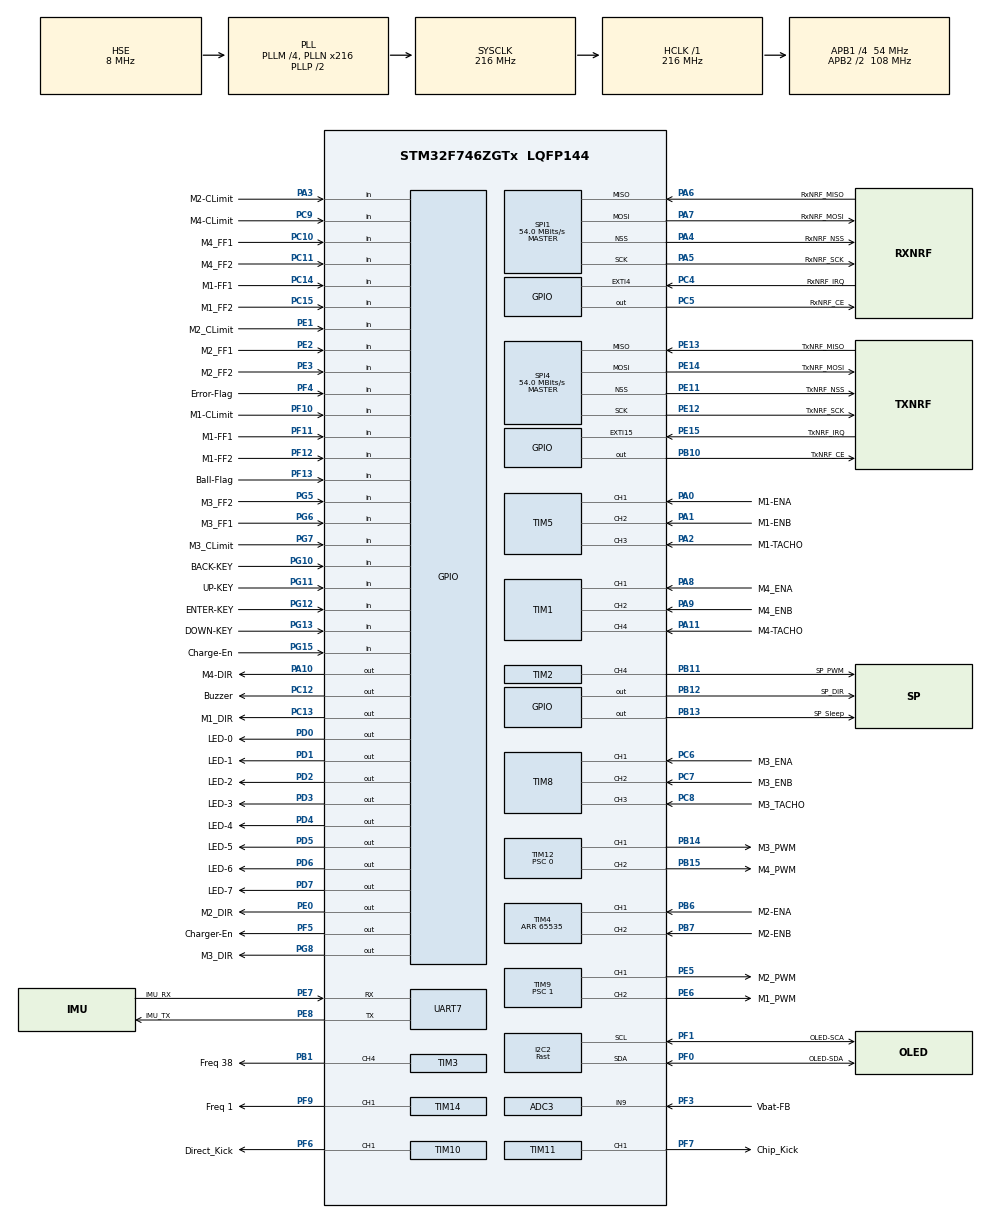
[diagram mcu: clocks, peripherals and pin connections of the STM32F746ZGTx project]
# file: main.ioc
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ADC3.Channel-9\#ChannelRegularConversion=ADC_CHANNEL_9
ADC3.ClockPrescaler=ADC_CLOCK_SYNC_PCLK_DIV4
ADC3.ContinuousConvMode=ENABLE
ADC3.DMAContinuousRequests=DISABLE
ADC3.DataAlign=ADC_DATAALIGN_RIGHT
ADC3.DiscontinuousConvMode=DISABLE
ADC3.EOCSelection=ADC_EOC_SINGLE_CONV
ADC3.EnableAnalogWatchDog=false
ADC3.ExternalTrigConv=ADC_SOFTWARE_START
ADC3.ExternalTrigConvEdge=ADC_EXTERNALTRIGCONVEDGE_NONE
ADC3.InjNumberOfConversion=0
ADC3.NbrOfConversion=1
ADC3.NbrOfConversionFlag=1
ADC3.Rank-9\#ChannelRegularConversion=1
ADC3.Resolution=ADC_RESOLUTION_10B
ADC3.SamplingTime-9\#ChannelRegularConversion=ADC_SAMPLETIME_480CYCLES
ADC3.ScanConvMode=DISABLE
I2C2.I2C_Speed_Mode=I2C_Fast
I2C2.Timing=0x6000030D
Mcu.Family=STM32F7
Mcu.Name=STM32F746ZGTx
Mcu.Package=LQFP144
NVIC.ADC_IRQn=true\:0\:0\:false\:false\:true\:true
NVIC.PriorityGroup=NVIC_PRIORITYGROUP_4
NVIC.TIM6_DAC_IRQn=true\:0\:0\:false\:false\:true\:true
NVIC.TIM7_IRQn=true\:0\:0\:false\:false\:true\:true
NVIC.TIM8_UP_TIM13_IRQn=true\:0\:0\:false\:false\:true\:true
NVIC.UART7_IRQn=true\:0\:0\:false\:false\:true\:true
PA0/WKUP.GPIO_Label=M1-ENA
PA0/WKUP.Signal=S_TIM5_CH1
PA1.GPIO_Label=M1-ENB
PA1.Signal=S_TIM5_CH2
PA10.GPIO_Label=M4-DIR
PA10.Signal=GPIO_Output
PA11.GPIO_Label=M4-TACHO
PA11.Signal=S_TIM1_CH4
PA13.Mode=Serial_Wire
PA13.Signal=SYS_JTMS-SWDIO
PA14.Mode=Serial_Wire
PA14.Signal=SYS_JTCK-SWCLK
PA2.GPIO_Label=M1-TACHO
PA2.Signal=S_TIM5_CH3
PA3.GPIO_Label=M2-CLimit
PA3.Signal=GPIO_Input
PA4.GPIO_Label=RxNRF_NSS
PA4.Mode=NSS_Signal_Hard_Output
PA4.Signal=SPI1_NSS
PA5.GPIO_Label=RxNRF_SCK
PA5.Mode=Full_Duplex_Master
PA5.Signal=SPI1_SCK
PA6.GPIO_Label=RxNRF_MISO
PA6.Mode=Full_Duplex_Master
PA6.Signal=SPI1_MISO
PA7.GPIO_Label=RxNRF_MOSI
PA7.Mode=Full_Duplex_Master
PA7.Signal=SPI1_MOSI
PA8.GPIO_Label=M4_ENA
PA8.Signal=S_TIM1_CH1
PA9.GPIO_Label=M4_ENB
PA9.Signal=S_TIM1_CH2
PB1.GPIO_Label=Freq 38
PB1.GPIO_Speed=GPIO_SPEED_FREQ_VERY_HIGH
PB1.Signal=S_TIM3_CH4
PB10.GPIO_Label=TxNRF_CE
PB10.Signal=GPIO_Output
PB11.GPIO_Label=SP_PWM
PB11.Signal=S_TIM2_CH4
PB12.GPIO_Label=SP_DIR
PB12.Signal=GPIO_Output
PB13.GPIO_Label=SP_Sleep
PB13.Signal=GPIO_Output
PB14.GPIO_Label=M3_PWM
PB14.GPIO_Speed=GPIO_SPEED_FREQ_HIGH
PB14.Signal=S_TIM12_CH1
PB15.GPIO_Label=M4_PWM
PB15.GPIO_Speed=GPIO_SPEED_FREQ_HIGH
PB15.Signal=S_TIM12_CH2
PB6.GPIO_Label=M2-ENA
PB6.Signal=S_TIM4_CH1
PB7.GPIO_Label=M2-ENB
PB7.Signal=S_TIM4_CH2
PB9.GPIO_Label=M2_TACHO
PB9.Signal=S_TIM4_CH4
PC10.GPIO_Label=M4_FF1
PC10.Signal=GPIO_Input
PC11.GPIO_Label=M4_FF2
PC11.Signal=GPIO_Input
PC12.GPIO_Label=Buzzer
PC12.Signal=GPIO_Output
PC13.GPIO_Label=M1_DIR
PC13.Signal=GPIO_Output
PC14/OSC32_IN.GPIO_Label=M1-FF1
PC14/OSC32_IN.Signal=GPIO_Input
PC15/OSC32_OUT.GPIO_Label=M1_FF2
PC15/OSC32_OUT.Signal=GPIO_Input
PC4.GPIO_Label=RxNRF_IRQ
PC4.Signal=GPXTI4
PC5.GPIO_Label=RxNRF_CE
PC5.Signal=GPIO_Output
PC6.GPIO_Label=M3_ENA
PC6.Signal=S_TIM8_CH1
PC7.GPIO_Label=M3_ENB
PC7.Signal=S_TIM8_CH2
PC8.GPIO_Label=M3_TACHO
PC8.Signal=S_TIM8_CH3
PC9.GPIO_Label=M4-CLimit
PC9.Signal=GPIO_Input
PD0.GPIO_Label=LED-0
PD0.Signal=GPIO_Output
PD1.GPIO_Label=LED-1
PD1.Signal=GPIO_Output
PD2.GPIO_Label=LED-2
PD2.Signal=GPIO_Output
PD3.GPIO_Label=LED-3
PD3.Signal=GPIO_Output
PD4.GPIO_Label=LED-4
PD4.Signal=GPIO_Output
PD5.GPIO_Label=LED-5
PD5.Signal=GPIO_Output
PD6.GPIO_Label=LED-6
PD6.Signal=GPIO_Output
PD7.GPIO_Label=LED-7
PD7.Signal=GPIO_Output
PE0.GPIO_Label=M2_DIR
PE0.Signal=GPIO_Output
PE1.GPIO_Label=M2_CLimit
PE1.Signal=GPIO_Input
PE11.GPIO_Label=TxNRF_NSS
PE11.Mode=NSS_Signal_Hard_Output
PE11.Signal=SPI4_NSS
PE12.GPIO_Label=TxNRF_SCK
PE12.Mode=Full_Duplex_Master
PE12.Signal=SPI4_SCK
PE13.GPIO_Label=TxNRF_MISO
PE13.Mode=Full_Duplex_Master
PE13.Signal=SPI4_MISO
PE14.GPIO_Label=TxNRF_MOSI
PE14.Mode=Full_Duplex_Master
PE14.Signal=SPI4_MOSI
PE15.GPIO_Label=TxNRF_IRQ
PE15.Signal=GPXTI15
PE2.GPIO_Label=M2_FF1
PE2.Signal=GPIO_Input
PE3.GPIO_Label=M2_FF2
PE3.Signal=GPIO_Input
PE5.GPIO_Label=M2_PWM
PE5.GPIO_Speed=GPIO_SPEED_FREQ_HIGH
PE5.Signal=S_TIM9_CH1
PE6.GPIO_Label=M1_PWM
PE6.GPIO_Speed=GPIO_SPEED_FREQ_HIGH
PE6.Signal=S_TIM9_CH2
PE7.GPIO_Label=IMU_RX
PE7.Mode=Asynchronous
PE7.Signal=UART7_RX
PE8.GPIO_Label=IMU_TX
PE8.Mode=Asynchronous
PE8.Signal=UART7_TX
PF0.GPIO_Label=OLED-SDA
PF0.Mode=I2C
PF0.Signal=I2C2_SDA
PF1.GPIO_Label=OLED-SCA
PF1.Mode=I2C
PF1.Signal=I2C2_SCL
PF10.GPIO_Label=M1-CLimit
PF10.Signal=GPIO_Input
PF11.GPIO_Label=M1-FF1
PF11.Signal=GPIO_Input
PF12.GPIO_Label=M1-FF2
PF12.Signal=GPIO_Input
PF13.GPIO_Label=Ball-Flag
PF13.Signal=GPIO_Input
PF3.GPIO_Label=Vbat-FB
PF3.Mode=IN9
PF3.Signal=ADC3_IN9
PF4.GPIO_Label=Error-Flag
PF4.Signal=GPIO_Input
PF5.GPIO_Label=Charger-En
PF5.Signal=GPIO_Output
PF6.GPIO_Label=Direct_Kick
PF6.GPIO_ModeDefaultPP=GPIO_MODE_AF_PP
PF6.GPIO_PuPd=GPIO_NOPULL
PF6.GPIO_Speed=GPIO_SPEED_FREQ_VERY_HIGH
PF6.Signal=S_TIM10_CH1
PF7.GPIO_Label=Chip_Kick
PF7.GPIO_Speed=GPIO_SPEED_FREQ_VERY_HIGH
PF7.Signal=S_TIM11_CH1
PF9.GPIO_Label=Freq 1 
PF9.GPIO_Speed=GPIO_SPEED_FREQ_VERY_HIGH
PF9.Signal=S_TIM14_CH1
PG10.GPIO_Label=BACK-KEY
PG10.Signal=GPIO_Input
PG11.GPIO_Label=UP-KEY
PG11.Signal=GPIO_Input
PG12.GPIO_Label=ENTER-KEY
PG12.Signal=GPIO_Input
PG13.GPIO_Label=DOWN-KEY
PG13.Signal=GPIO_Input
PG15.GPIO_Label=Charge-En
PG15.Signal=GPIO_Input
PG5.GPIO_Label=M3_FF2
PG5.Signal=GPIO_Input
PG6.GPIO_Label=M3_FF1
PG6.Signal=GPIO_Input
PG7.GPIO_Label=M3_CLimit
PG7.Signal=GPIO_Input
PG8.GPIO_Label=M3_DIR
PG8.Signal=GPIO_Output
PH0/OSC_IN.Mode=HSE-External-Oscillator
PH0/OSC_IN.Signal=RCC_OSC_IN
PH1/OSC_OUT.Mode=HSE-External-Oscillator
PH1/OSC_OUT.Signal=RCC_OSC_OUT
ProjectManager.HeapSize=0x200
ProjectManager.StackSize=0x400
ProjectManager.TargetToolchain=MDK-ARM V5
RCC.AHBFreq_Value=216000000
RCC.APB1CLKDivider=RCC_HCLK_DIV4
RCC.APB1Freq_Value=54000000
RCC.APB1TimFreq_Value=108000000
RCC.APB2CLKDivider=RCC_HCLK_DIV2
RCC.APB2Freq_Value=108000000
RCC.APB2TimFreq_Value=216000000
RCC.CortexFreq_Value=216000000
RCC.HCLKFreq_Value=216000000
RCC.HSE_VALUE=8000000
RCC.HSI_VALUE=16000000
RCC.LSE_VALUE=32768
RCC.PLLM=4
RCC.PLLN=216
RCC.PLLSourceVirtual=RCC_PLLSOURCE_HSE
RCC.SYSCLKFreq_VALUE=216000000
RCC.SYSCLKSource=RCC_SYSCLKSOURCE_PLLCLK
RCC.USBFreq_Value=216000000
RCC.VCOOutputFreq_Value=432000000
SH.S_TIM10_CH1.0=TIM10_CH1,PWM Generation1 CH1
SH.S_TIM11_CH1.0=TIM11_CH1,PWM Generation1 CH1
SH.S_TIM12_CH1.0=TIM12_CH1,PWM Generation1 CH1
SH.S_TIM12_CH2.0=TIM12_CH2,PWM Generation2 CH2
SH.S_TIM14_CH1.0=TIM14_CH1,PWM Generation1 CH1
SH.S_TIM1_CH1.0=TIM1_CH1,Encoder_Interface
SH.S_TIM1_CH2.0=TIM1_CH2,Encoder_Interface
SH.S_TIM1_CH4.0=TIM1_CH4,Input_Capture4_from_TI4
SH.S_TIM2_CH4.0=TIM2_CH4,PWM Generation4 CH4
SH.S_TIM3_CH4.0=TIM3_CH4,PWM Generation4 CH4
SH.S_TIM4_CH1.0=TIM4_CH1,Encoder_Interface
SH.S_TIM4_CH2.0=TIM4_CH2,Encoder_Interface
SH.S_TIM4_CH4.0=TIM4_CH4
SH.S_TIM5_CH1.0=TIM5_CH1,Encoder_Interface
SH.S_TIM5_CH2.0=TIM5_CH2,Encoder_Interface
SH.S_TIM5_CH3.0=TIM5_CH3,Input_Capture3_from_TI3
SH.S_TIM8_CH1.0=TIM8_CH1,Encoder_Interface
SH.S_TIM8_CH2.0=TIM8_CH2,Encoder_Interface
SH.S_TIM8_CH3.0=TIM8_CH3,Input_Capture3_from_TI3
SH.S_TIM9_CH1.0=TIM9_CH1,PWM Generation1 CH1
SH.S_TIM9_CH2.0=TIM9_CH2,PWM Generation2 CH2
SPI1.BaudRatePrescaler=SPI_BAUDRATEPRESCALER_2
SPI1.CalculateBaudRate=54.0 MBits/s
SPI1.Direction=SPI_DIRECTION_2LINES
SPI1.Mode=SPI_MODE_MASTER
SPI1.VirtualNSS=VM_NSSHARD
SPI1.VirtualType=VM_MASTER
SPI4.BaudRatePrescaler=SPI_BAUDRATEPRESCALER_2
SPI4.CalculateBaudRate=54.0 MBits/s
SPI4.Direction=SPI_DIRECTION_2LINES
SPI4.Mode=SPI_MODE_MASTER
SPI4.VirtualNSS=VM_NSSHARD
SPI4.VirtualType=VM_MASTER
TIM1.Channel-Input_Capture4_from_TI4=TIM_CHANNEL_4
TIM10.Channel=TIM_CHANNEL_1
TIM10.OCFastMode_PWM=TIM_OCFAST_ENABLE
TIM10.OCMode_PWM=TIM_OCMODE_PWM2
TIM10.Period=65535
TIM10.Prescaler=11
TIM11.Channel=TIM_CHANNEL_1
TIM11.Period=65535
TIM11.Prescaler=11
TIM12.Channel-PWM\ Generation1\ CH1=TIM_CHANNEL_1
TIM12.Channel-PWM\ Generation2\ CH2=TIM_CHANNEL_2
TIM12.Period=4999
TIM12.Prescaler=0
TIM13.Period=9999
TIM13.Prescaler=1079
TIM14.Channel=TIM_CHANNEL_1
TIM14.OCMode_PWM=TIM_OCMODE_PWM1
TIM14.OCPolarity_1=TIM_OCPOLARITY_HIGH
TIM14.Period=53999
TIM14.Prescaler=1
TIM14.Pulse=27000
TIM2.Channel-PWM\ Generation4\ CH4=TIM_CHANNEL_4
TIM2.Period=4999
TIM3.Channel-PWM\ Generation4\ CH4=TIM_CHANNEL_4
TIM3.OCPolarity_4=TIM_OCPOLARITY_HIGH
TIM3.Period=2841
TIM3.Pulse-PWM\ Generation4\ CH4=1421
TIM4.EncoderMode=TIM_ENCODERMODE_TI12
TIM4.IC1Filter=15
TIM4.IC2Filter=15
TIM4.Period=65535
TIM5.Channel-Input_Capture3_from_TI3=TIM_CHANNEL_3
TIM6.Period=9999
TIM6.Prescaler=107
TIM7.Period=9999
TIM7.Prescaler=107
TIM8.Channel-Input_Capture3_from_TI3=TIM_CHANNEL_3
TIM9.Channel-PWM\ Generation1\ CH1=TIM_CHANNEL_1
TIM9.Channel-PWM\ Generation2\ CH2=TIM_CHANNEL_2
TIM9.OCFastMode_PWM-PWM\ Generation2\ CH2=TIM_OCFAST_ENABLE
TIM9.OCMode_PWM-PWM\ Generation2\ CH2=TIM_OCMODE_PWM1
TIM9.OCPolarity_2=TIM_OCPOLARITY_HIGH
TIM9.Period=4999
TIM9.Prescaler=1
VP_TIM10_VS_ClockSourceINT.Mode=Enable_Timer
VP_TIM10_VS_OPM.Mode=OPM_bit
VP_TIM11_VS_ClockSourceINT.Mode=Enable_Timer
VP_TIM11_VS_OPM.Mode=OPM_bit
VP_TIM12_VS_ClockSourceINT.Mode=Internal
VP_TIM13_VS_ClockSourceINT.Mode=Enable_Timer
VP_TIM14_VS_ClockSourceINT.Mode=Enable_Timer
VP_TIM6_VS_ClockSourceINT.Mode=Enable_Timer
VP_TIM7_VS_ClockSourceINT.Mode=Enable_Timer
VP_TIM9_VS_ClockSourceINT.Mode=Internal
board=main

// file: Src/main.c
/**
  ******************************************************************************
  * @file           : main.c
  * @brief          : Main program body
  ******************************************************************************
  ** This notice applies to any and all portions of this file
  * that are not between comment pairs USER CODE BEGIN and
  * USER CODE END. Other portions of this file, whether
  * inserted by the user or by software development tools
  * are owned by their respective copyright owners.
  *
  * COPYRIGHT(c) 2018 STMicroelectronics
  *
  * Redistribution and use in source and binary forms, with or without modification,
  * are permitted provided that the following conditions are met:
  *   1. Redistributions of source code must retain the above copyright notice,
  *      this list of conditions and the following disclaimer.
  *   2. Redistributions in binary form must reproduce the above copyright notice,
  *      this list of conditions and the following disclaimer in the documentation
  *      and/or other materials provided with the distribution.
  *   3. Neither the name of STMicroelectronics nor the names of its contributors
  *      may be used to endorse or promote products derived from this software
  *      without specific prior written permission.
  *
  * THIS SOFTWARE IS PROVIDED BY THE COPYRIGHT HOLDERS AND CONTRIBUTORS "AS IS"
  * AND ANY EXPRESS OR IMPLIED WARRANTIES, INCLUDING, BUT NOT LIMITED TO, THE
  * IMPLIED WARRANTIES OF MERCHANTABILITY AND FITNESS FOR A PARTICULAR PURPOSE ARE
  * DISCLAIMED. IN NO EVENT SHALL THE COPYRIGHT HOLDER OR CONTRIBUTORS BE LIABLE
  * FOR ANY DIRECT, INDIRECT, INCIDENTAL, SPECIAL, EXEMPLARY, OR CONSEQUENTIAL
  * DAMAGES (INCLUDING, BUT NOT LIMITED TO, PROCUREMENT OF SUBSTITUTE GOODS OR
  * SERVICES; LOSS OF USE, DATA, OR PROFITS; OR BUSINESS INTERRUPTION) HOWEVER
  * CAUSED AND ON ANY THEORY OF LIABILITY, WHETHER IN CONTRACT, STRICT LIABILITY,
  * OR TORT (INCLUDING NEGLIGENCE OR OTHERWISE) ARISING IN ANY WAY OUT OF THE USE
  * OF THIS SOFTWARE, EVEN IF ADVISED OF THE POSSIBILITY OF SUCH DAMAGE.
  *
  ******************************************************************************
  */
#include "main.h"
#include "stm32f7xx_hal.h"

/* USER CODE BEGIN Includes */

#include "stdbool.h"
#include "ssd1306.h"
#include "fonts.h"
#include <stdio.h>
#include <math.h>
#include <string.h>

#define PERIOD 0.01
#define FRAME_RATE 1/PERIOD

// variables for the pid function that is actually not a function
#define  PULSE_PER_ROUND 360
#define  ENCODER_READ_PERIOD 0.002
#define  ENCODER_READ_FRAME_RATE 1/ENCODER_READ_PERIOD
#define  SECONDE_TO_MINUTE 60

/* USER CODE END Includes */

ADC_HandleTypeDef hadc3;

I2C_HandleTypeDef hi2c2;

SPI_HandleTypeDef hspi1;
SPI_HandleTypeDef hspi4;

TIM_HandleTypeDef htim1;
TIM_HandleTypeDef htim2;
TIM_HandleTypeDef htim3;
TIM_HandleTypeDef htim4;
TIM_HandleTypeDef htim5;
TIM_HandleTypeDef htim6;
TIM_HandleTypeDef htim7;
TIM_HandleTypeDef htim8;
TIM_HandleTypeDef htim9;
TIM_HandleTypeDef htim10;
TIM_HandleTypeDef htim11;
TIM_HandleTypeDef htim12;
TIM_HandleTypeDef htim13;
TIM_HandleTypeDef htim14;

UART_HandleTypeDef huart7;

/* USER CODE BEGIN PV */
/* Private variables ---------------------------------------------------------*/
float EN1_RPM;
uint32_t tmp=0;

uint8_t direction;
int PWM,M_PWM,SP_PWM;

uint32_t start=0;
float Battery;
float value;
char buffer1[10];
char buffer2[8];

// refernce and pid related constants
float Input_Speed = 0;
float output =0;

//errors variables
float LastError = 0;
float Error = 0;

float DifferentialError=0,
			IntegralError=0;

float Last_RPM_EN1,
			DEN1,
			Last_Filter_EN1,
			MAX_DEN = 6000;

float KP=2,
			KI=20,
			KD=0.05,
			lambda = 0.997,
			MaxIntegral = 5000;

float COEFF = 4.16;
/* USER CODE END PV */

void SystemClock_Config(void);
static void MX_GPIO_Init(void);
static void MX_ADC3_Init(void);
static void MX_I2C2_Init(void);
static void MX_SPI1_Init(void);
static void MX_SPI4_Init(void);
static void MX_TIM1_Init(void);
static void MX_TIM2_Init(void);
static void MX_TIM3_Init(void);
static void MX_TIM5_Init(void);
static void MX_TIM8_Init(void);
static void MX_TIM9_Init(void);
static void MX_TIM10_Init(void);
static void MX_TIM11_Init(void);
static void MX_TIM12_Init(void);
static void MX_TIM14_Init(void);
static void MX_UART7_Init(void);
static void MX_TIM6_Init(void);
static void MX_TIM13_Init(void);
static void MX_TIM7_Init(void);
static void MX_TIM4_Init(void);

void HAL_TIM_MspPostInit(TIM_HandleTypeDef *htim);

/* USER CODE BEGIN PFP */
/* Private function prototypes -----------------------------------------------*/
bool PB_UPKey(void);
bool PB_DOWNKey(void);
bool PB_BACKKey(void);
bool PB_ENTERKey(void);
void OLED_Preview(float PWM);
void Set_PWM (int M1_PWM,int M2_PWM,int M3_PWM,int M4_PWM,int SP_PWM);
float Filter_Encoder_Data(float enc_data , float coeff , float last_filter);

void PID(void);
void Scan_Keys(void);

/* USER CODE END PFP */

/* USER CODE BEGIN 0 */
void HAL_TIM_PeriodElapsedCallback(TIM_HandleTypeDef *htim)
{
	if(htim->Instance == TIM6)  //10ms
	{

			direction = __HAL_TIM_IS_TIM_COUNTING_DOWN(&htim4);

		if(!direction)
			EN1_RPM = (TIM4->CNT) - tmp;
		else
		{
			EN1_RPM = tmp - (TIM4->CNT);
			EN1_RPM*=-1;
		}
			EN1_RPM*=COEFF;

		DEN1=EN1_RPM-Last_RPM_EN1;

		if(fabs(DEN1) > MAX_DEN)
		EN1_RPM = Last_RPM_EN1;

		Last_RPM_EN1=EN1_RPM;
		EN1_RPM = Filter_Encoder_Data(EN1_RPM , 6 , Last_Filter_EN1);
		Last_Filter_EN1 = EN1_RPM;

		if(EN1_RPM>6500) EN1_RPM=6500;
		if(EN1_RPM<-6500) EN1_RPM=-6500;

			tmp = TIM4->CNT;

	}

	if(htim->Instance == TIM7) //10ms
	{
			PID();
	}

	if(htim->Instance == TIM13) //100ms
	{
				Scan_Keys();

	}

}

/* USER CODE END 0 */

int main(void)
{

  /* MCU Configuration----------------------------------------------------------*/

  /* Reset of all peripherals, Initializes the Flash interface and the Systick. */
  HAL_Init();

  /* Configure the system clock */
  SystemClock_Config();

  /* Initialize all configured peripherals */
  MX_GPIO_Init();
  MX_ADC3_Init();
  MX_I2C2_Init();
  MX_SPI1_Init();
  MX_SPI4_Init();
  MX_TIM1_Init();
  MX_TIM2_Init();
  MX_TIM3_Init();
  MX_TIM5_Init();
  MX_TIM8_Init();
  MX_TIM9_Init();
  MX_TIM10_Init();
  MX_TIM11_Init();
  MX_TIM12_Init();
  MX_TIM14_Init();
  MX_UART7_Init();
  MX_TIM6_Init();
  MX_TIM13_Init();
  MX_TIM7_Init();
  MX_TIM4_Init();
  /* USER CODE BEGIN 2 */

	ssd1306_Init();
//	hadc3.Init.NbrOfConversion=1;
//	HAL_ADC_Init(&hadc3);
//	HAL_ADC_Start_IT (&hadc3);  // start ADC in interrupt mode

	HAL_TIM_PWM_Start(&htim14,TIM_CHANNEL_1); // Freq 1
	HAL_TIM_PWM_Start(&htim3,TIM_CHANNEL_4);	// Freq 38
//	__HAL_TIM_SetCompare(&htim14,TIM_CHANNEL_1,freq1);
//	__HAL_TIM_SetCompare(&htim3,TIM_CHANNEL_4,freq38);
	HAL_TIM_PWM_Start(&htim9,TIM_CHANNEL_2);  // M1
	HAL_TIM_PWM_Start(&htim9,TIM_CHANNEL_1);  // M2
	HAL_TIM_PWM_Start(&htim12,TIM_CHANNEL_1); // M3
	HAL_TIM_PWM_Start(&htim12,TIM_CHANNEL_2); // M4
	HAL_TIM_PWM_Start(&htim2,TIM_CHANNEL_4);  // SP

	HAL_TIM_Encoder_Start(&htim4, TIM_CHANNEL_1);
	HAL_TIM_Encoder_Start(&htim4, TIM_CHANNEL_2);
//	HAL_TIM_IC_Start(&htim4,TIM_CHANNEL_4);

	HAL_TIM_Base_Start_IT(&htim6);
	HAL_TIM_Base_Start_IT(&htim7);
	HAL_TIM_Base_Start_IT(&htim13);

//	__HAL_TIM_SetCounter(&htim4,32768);

	HAL_GPIO_WritePin(SP_Sleep_GPIO_Port,SP_Sleep_Pin,GPIO_PIN_SET); // SP
	HAL_GPIO_WritePin(SP_DIR_GPIO_Port,SP_DIR_Pin,GPIO_PIN_RESET);	 // SP

	HAL_GPIO_WritePin(M1_DIR_GPIO_Port,M1_DIR_Pin,GPIO_PIN_RESET);	// M1
	HAL_GPIO_WritePin(M2_DIR_GPIO_Port,M2_DIR_Pin,GPIO_PIN_RESET);	// M2
	HAL_GPIO_WritePin(M3_DIR_GPIO_Port,M3_DIR_Pin,GPIO_PIN_RESET);	// M3
	HAL_GPIO_WritePin(M4_DIR_GPIO_Port,M4_DIR_Pin,GPIO_PIN_RESET);	// M4

	HAL_GPIO_WritePin(Buzzer_GPIO_Port,Buzzer_Pin,GPIO_PIN_SET);
	HAL_Delay(150);
	HAL_GPIO_WritePin(Buzzer_GPIO_Port,Buzzer_Pin,GPIO_PIN_RESET);
	HAL_Delay(200);
	HAL_GPIO_WritePin(Buzzer_GPIO_Port,Buzzer_Pin,GPIO_PIN_SET);
	HAL_Delay(150);
	HAL_GPIO_WritePin(Buzzer_GPIO_Port,Buzzer_Pin,GPIO_PIN_RESET);

	ssd1306_Init();
	ssd1306_Fill(Black);
	ssd1306_UpdateScreen();
	ssd1306_SetCursor(40,0);
	ssd1306_WriteString("MRL",Font_16x26,White);
	ssd1306_SetCursor(11,30);
	ssd1306_WriteString("MAIN BOARD v1.0",Font_7x10,White);
	ssd1306_SetCursor(20,45);
	ssd1306_WriteString("SSL 2018",Font_11x18,White);
	ssd1306_UpdateScreen();
	HAL_Delay(1500);
	ssd1306_Fill(Black);
	ssd1306_UpdateScreen();

	HAL_GPIO_TogglePin(LED_0_GPIO_Port,LED_0_Pin);
	HAL_GPIO_TogglePin(LED_1_GPIO_Port,LED_1_Pin);
//	OLED_Preview(Input_Speed);
  /* USER CODE END 2 */

  /* Infinite loop */
  /* USER CODE BEGIN WHILE */
  while (1)
	{
//		Set_PWM(PWM,PWM,PWM,PWM,PWM);

//			if(PB_UPKey())
//			{
//			PWM+=10;
//			if(PWM > 2500)
//			PWM = 2500;
//			OLED_Preview(PWM);
////			Set_PWM(PWM,PWM,PWM,PWM,PWM);
//			}
//			if(PB_DOWNKey())
//			{
//			PWM-=10;
//			if(PWM < 5)
//			PWM = 0;
//			OLED_Preview(PWM);
////			Set_PWM(PWM,PWM,PWM,PWM,PWM);
//			}
//
//			if(PB_BACKKey())
//			{
//
//			PWM = 0;
//			OLED_Preview(PWM);
////			Set_PWM(PWM,PWM,PWM,PWM,PWM);
//			}
			sprintf(buffer1,"SPEED=%4.0f",Input_Speed);
			ssd1306_SetCursor(0,0);
			ssd1306_WriteString(buffer1,Font_11x18,White);
			sprintf(buffer2,"RPM=%4.0f",EN1_RPM);
			ssd1306_SetCursor(0,30);
			ssd1306_WriteString(buffer2,Font_11x18,White);
			ssd1306_UpdateScreen();

  /* USER CODE END WHILE */

  }

}

void SystemClock_Config(void)
{

  RCC_OscInitTypeDef RCC_OscInitStruct;
  RCC_ClkInitTypeDef RCC_ClkInitStruct;
  RCC_PeriphCLKInitTypeDef PeriphClkInitStruct;

    /**Configure the main internal regulator output voltage
    */
  __HAL_RCC_PWR_CLK_ENABLE();

  __HAL_PWR_VOLTAGESCALING_CONFIG(PWR_REGULATOR_VOLTAGE_SCALE1);

    /**Initializes the CPU, AHB and APB busses clocks
    */
  RCC_OscInitStruct.OscillatorType = RCC_OSCILLATORTYPE_HSE;
  RCC_OscInitStruct.HSEState = RCC_HSE_ON;
  RCC_OscInitStruct.PLL.PLLState = RCC_PLL_ON;
  RCC_OscInitStruct.PLL.PLLSource = RCC_PLLSOURCE_HSE;
  RCC_OscInitStruct.PLL.PLLM = 4;
  RCC_OscInitStruct.PLL.PLLN = 216;
  RCC_OscInitStruct.PLL.PLLP = RCC_PLLP_DIV2;
  RCC_OscInitStruct.PLL.PLLQ = 2;
  if (HAL_RCC_OscConfig(&RCC_OscInitStruct) != HAL_OK)
  {
    _Error_Handler(__FILE__, __LINE__);
  }

    /**Activate the Over-Drive mode
    */
  if (HAL_PWREx_EnableOverDrive() != HAL_OK)
  {
    _Error_Handler(__FILE__, __LINE__);
  }

    /**Initializes the CPU, AHB and APB busses clocks
    */
  RCC_ClkInitStruct.ClockType = RCC_CLOCKTYPE_HCLK|RCC_CLOCKTYPE_SYSCLK
                              |RCC_CLOCKTYPE_PCLK1|RCC_CLOCKTYPE_PCLK2;
  RCC_ClkInitStruct.SYSCLKSource = RCC_SYSCLKSOURCE_PLLCLK;
  RCC_ClkInitStruct.AHBCLKDivider = RCC_SYSCLK_DIV1;
  RCC_ClkInitStruct.APB1CLKDivider = RCC_HCLK_DIV4;
  RCC_ClkInitStruct.APB2CLKDivider = RCC_HCLK_DIV2;

  if (HAL_RCC_ClockConfig(&RCC_ClkInitStruct, FLASH_LATENCY_7) != HAL_OK)
  {
    _Error_Handler(__FILE__, __LINE__);
  }

  PeriphClkInitStruct.PeriphClockSelection = RCC_PERIPHCLK_UART7|RCC_PERIPHCLK_I2C2;
  PeriphClkInitStruct.Uart7ClockSelection = RCC_UART7CLKSOURCE_PCLK1;
  PeriphClkInitStruct.I2c2ClockSelection = RCC_I2C2CLKSOURCE_PCLK1;
  if (HAL_RCCEx_PeriphCLKConfig(&PeriphClkInitStruct) != HAL_OK)
  {
    _Error_Handler(__FILE__, __LINE__);
  }

    /**Configure the Systick interrupt time
    */
  HAL_SYSTICK_Config(HAL_RCC_GetHCLKFreq()/1000);

    /**Configure the Systick
    */
  HAL_SYSTICK_CLKSourceConfig(SYSTICK_CLKSOURCE_HCLK);

  /* SysTick_IRQn interrupt configuration */
  HAL_NVIC_SetPriority(SysTick_IRQn, 0, 0);
}

/* ADC3 init function */
static void MX_ADC3_Init(void)
{

  ADC_ChannelConfTypeDef sConfig;

    /**Configure the global features of the ADC (Clock, Resolution, Data Alignment and number of conversion)
    */
  hadc3.Instance = ADC3;
  hadc3.Init.ClockPrescaler = ADC_CLOCK_SYNC_PCLK_DIV4;
  hadc3.Init.Resolution = ADC_RESOLUTION_10B;
  hadc3.Init.ScanConvMode = DISABLE;
  hadc3.Init.ContinuousConvMode = ENABLE;
  hadc3.Init.DiscontinuousConvMode = DISABLE;
  hadc3.Init.ExternalTrigConvEdge = ADC_EXTERNALTRIGCONVEDGE_NONE;
  hadc3.Init.ExternalTrigConv = ADC_SOFTWARE_START;
  hadc3.Init.DataAlign = ADC_DATAALIGN_RIGHT;
  hadc3.Init.NbrOfConversion = 1;
  hadc3.Init.DMAContinuousRequests = DISABLE;
  hadc3.Init.EOCSelection = ADC_EOC_SINGLE_CONV;
  if (HAL_ADC_Init(&hadc3) != HAL_OK)
  {
    _Error_Handler(__FILE__, __LINE__);
  }

    /**Configure for the selected ADC regular channel its corresponding rank in the sequencer and its sample time.
    */
  sConfig.Channel = ADC_CHANNEL_9;
  sConfig.Rank = ADC_REGULAR_RANK_1;
  sConfig.SamplingTime = ADC_SAMPLETIME_480CYCLES;
  if (HAL_ADC_ConfigChannel(&hadc3, &sConfig) != HAL_OK)
  {
    _Error_Handler(__FILE__, __LINE__);
  }

}

/* I2C2 init function */
static void MX_I2C2_Init(void)
{

  hi2c2.Instance = I2C2;
  hi2c2.Init.Timing = 0x6000030D;
  hi2c2.Init.OwnAddress1 = 0;
  hi2c2.Init.AddressingMode = I2C_ADDRESSINGMODE_7BIT;
  hi2c2.Init.DualAddressMode = I2C_DUALADDRESS_DISABLE;
  hi2c2.Init.OwnAddress2 = 0;
  hi2c2.Init.OwnAddress2Masks = I2C_OA2_NOMASK;
  hi2c2.Init.GeneralCallMode = I2C_GENERALCALL_DISABLE;
  hi2c2.Init.NoStretchMode = I2C_NOSTRETCH_DISABLE;
  if (HAL_I2C_Init(&hi2c2) != HAL_OK)
  {
    _Error_Handler(__FILE__, __LINE__);
  }

    /**Configure Analogue filter
    */
  if (HAL_I2CEx_ConfigAnalogFilter(&hi2c2, I2C_ANALOGFILTER_ENABLE) != HAL_OK)
  {
    _Error_Handler(__FILE__, __LINE__);
  }

    /**Configure Digital filter
    */
  if (HAL_I2CEx_ConfigDigitalFilter(&hi2c2, 0) != HAL_OK)
  {
    _Error_Handler(__FILE__, __LINE__);
  }

}

/* SPI1 init function */
static void MX_SPI1_Init(void)
{

  /* SPI1 parameter configuration*/
  hspi1.Instance = SPI1;
  hspi1.Init.Mode = SPI_MODE_MASTER;
  hspi1.Init.Direction = SPI_DIRECTION_2LINES;
  hspi1.Init.DataSize = SPI_DATASIZE_4BIT;
  hspi1.Init.CLKPolarity = SPI_POLARITY_LOW;
  hspi1.Init.CLKPhase = SPI_PHASE_1EDGE;
  hspi1.Init.NSS = SPI_NSS_HARD_OUTPUT;
  hspi1.Init.BaudRatePrescaler = SPI_BAUDRATEPRESCALER_2;
  hspi1.Init.FirstBit = SPI_FIRSTBIT_MSB;
  hspi1.Init.TIMode = SPI_TIMODE_DISABLE;
  hspi1.Init.CRCCalculation = SPI_CRCCALCULATION_DISABLE;
  hspi1.Init.CRCPolynomial = 7;
  hspi1.Init.CRCLength = SPI_CRC_LENGTH_DATASIZE;
  hspi1.Init.NSSPMode = SPI_NSS_PULSE_ENABLE;
  if (HAL_SPI_Init(&hspi1) != HAL_OK)
  {
    _Error_Handler(__FILE__, __LINE__);
  }

}

/* SPI4 init function */
static void MX_SPI4_Init(void)
{

  /* SPI4 parameter configuration*/
  hspi4.Instance = SPI4;
  hspi4.Init.Mode = SPI_MODE_MASTER;
  hspi4.Init.Direction = SPI_DIRECTION_2LINES;
  hspi4.Init.DataSize = SPI_DATASIZE_4BIT;
  hspi4.Init.CLKPolarity = SPI_POLARITY_LOW;
  hspi4.Init.CLKPhase = SPI_PHASE_1EDGE;
  hspi4.Init.NSS = SPI_NSS_HARD_OUTPUT;
  hspi4.Init.BaudRatePrescaler = SPI_BAUDRATEPRESCALER_2;
  hspi4.Init.FirstBit = SPI_FIRSTBIT_MSB;
  hspi4.Init.TIMode = SPI_TIMODE_DISABLE;
  hspi4.Init.CRCCalculation = SPI_CRCCALCULATION_DISABLE;
  hspi4.Init.CRCPolynomial = 7;
  hspi4.Init.CRCLength = SPI_CRC_LENGTH_DATASIZE;
  hspi4.Init.NSSPMode = SPI_NSS_PULSE_ENABLE;
  if (HAL_SPI_Init(&hspi4) != HAL_OK)
  {
    _Error_Handler(__FILE__, __LINE__);
  }

}

/* TIM1 init function */
static void MX_TIM1_Init(void)
{

  TIM_Encoder_InitTypeDef sConfig;
  TIM_MasterConfigTypeDef sMasterConfig;
  TIM_IC_InitTypeDef sConfigIC;

  htim1.Instance = TIM1;
  htim1.Init.Prescaler = 0;
  htim1.Init.CounterMode = TIM_COUNTERMODE_UP;
  htim1.Init.Period = 0;
  htim1.Init.ClockDivision = TIM_CLOCKDIVISION_DIV1;
  htim1.Init.RepetitionCounter = 0;
  htim1.Init.AutoReloadPreload = TIM_AUTORELOAD_PRELOAD_DISABLE;
  if (HAL_TIM_IC_Init(&htim1) != HAL_OK)
  {
    _Error_Handler(__FILE__, __LINE__);
  }

  sConfig.EncoderMode = TIM_ENCODERMODE_TI1;
  sConfig.IC1Polarity = TIM_ICPOLARITY_RISING;
  sConfig.IC1Selection = TIM_ICSELECTION_DIRECTTI;
  sConfig.IC1Prescaler = TIM_ICPSC_DIV1;
  sConfig.IC1Filter = 0;
  sConfig.IC2Polarity = TIM_ICPOLARITY_RISING;
  sConfig.IC2Selection = TIM_ICSELECTION_DIRECTTI;
  sConfig.IC2Prescaler = TIM_ICPSC_DIV1;
  sConfig.IC2Filter = 0;
  if (HAL_TIM_Encoder_Init(&htim1, &sConfig) != HAL_OK)
  {
    _Error_Handler(__FILE__, __LINE__);
  }

  sMasterConfig.MasterOutputTrigger = TIM_TRGO_RESET;
  sMasterConfig.MasterOutputTrigger2 = TIM_TRGO2_RESET;
  sMasterConfig.MasterSlaveMode = TIM_MASTERSLAVEMODE_DISABLE;
  if (HAL_TIMEx_MasterConfigSynchronization(&htim1, &sMasterConfig) != HAL_OK)
  {
    _Error_Handler(__FILE__, __LINE__);
  }

  sConfigIC.ICPolarity = TIM_INPUTCHANNELPOLARITY_RISING;
  sConfigIC.ICSelection = TIM_ICSELECTION_DIRECTTI;
  sConfigIC.ICPrescaler = TIM_ICPSC_DIV1;
  sConfigIC.ICFilter = 0;
  if (HAL_TIM_IC_ConfigChannel(&htim1, &sConfigIC, TIM_CHANNEL_4) != HAL_OK)
  {
    _Error_Handler(__FILE__, __LINE__);
  }

}

/* TIM2 init function */
static void MX_TIM2_Init(void)
{

  TIM_MasterConfigTypeDef sMasterConfig;
  TIM_OC_InitTypeDef sConfigOC;

  htim2.Instance = TIM2;
  htim2.Init.Prescaler = 0;
  htim2.Init.CounterMode = TIM_COUNTERMODE_UP;
  htim2.Init.Period = 4999;
  htim2.Init.ClockDivision = TIM_CLOCKDIVISION_DIV1;
  htim2.Init.AutoReloadPreload = TIM_AUTORELOAD_PRELOAD_DISABLE;
  if (HAL_TIM_PWM_Init(&htim2) != HAL_OK)
  {
    _Error_Handler(__FILE__, __LINE__);
  }

  sMasterConfig.MasterOutputTrigger = TIM_TRGO_RESET;
  sMasterConfig.MasterSlaveMode = TIM_MASTERSLAVEMODE_DISABLE;
  if (HAL_TIMEx_MasterConfigSynchronization(&htim2, &sMasterConfig) != HAL_OK)
  {
    _Error_Handler(__FILE__, __LINE__);
  }

  sConfigOC.OCMode = TIM_OCMODE_PWM1;
  sConfigOC.Pulse = 0;
  sConfigOC.OCPolarity = TIM_OCPOLARITY_HIGH;
  sConfigOC.OCFastMode = TIM_OCFAST_DISABLE;
  if (HAL_TIM_PWM_ConfigChannel(&htim2, &sConfigOC, TIM_CHANNEL_4) != HAL_OK)
  {
    _Error_Handler(__FILE__, __LINE__);
  }

  HAL_TIM_MspPostInit(&htim2);

}

/* TIM3 init function */
static void MX_TIM3_Init(void)
{

  TIM_MasterConfigTypeDef sMasterConfig;
  TIM_OC_InitTypeDef sConfigOC;

  htim3.Instance = TIM3;
  htim3.Init.Prescaler = 0;
  htim3.Init.CounterMode = TIM_COUNTERMODE_UP;
  htim3.Init.Period = 2841;
  htim3.Init.ClockDivision = TIM_CLOCKDIVISION_DIV1;
  htim3.Init.AutoReloadPreload = TIM_AUTORELOAD_PRELOAD_DISABLE;
  if (HAL_TIM_PWM_Init(&htim3) != HAL_OK)
  {
    _Error_Handler(__FILE__, __LINE__);
  }

  sMasterConfig.MasterOutputTrigger = TIM_TRGO_RESET;
  sMasterConfig.MasterSlaveMode = TIM_MASTERSLAVEMODE_DISABLE;
  if (HAL_TIMEx_MasterConfigSynchronization(&htim3, &sMasterConfig) != HAL_OK)
  {
    _Error_Handler(__FILE__, __LINE__);
  }

  sConfigOC.OCMode = TIM_OCMODE_PWM1;
  sConfigOC.Pulse = 1421;
  sConfigOC.OCPolarity = TIM_OCPOLARITY_HIGH;
  sConfigOC.OCFastMode = TIM_OCFAST_DISABLE;
  if (HAL_TIM_PWM_ConfigChannel(&htim3, &sConfigOC, TIM_CHANNEL_4) != HAL_OK)
  {
    _Error_Handler(__FILE__, __LINE__);
  }

  HAL_TIM_MspPostInit(&htim3);

}

/* TIM4 init function */
static void MX_TIM4_Init(void)
{

  TIM_Encoder_InitTypeDef sConfig;
  TIM_MasterConfigTypeDef sMasterConfig;

  htim4.Instance = TIM4;
  htim4.Init.Prescaler = 0;
  htim4.Init.CounterMode = TIM_COUNTERMODE_UP;
  htim4.Init.Period = 65535;
  htim4.Init.ClockDivision = TIM_CLOCKDIVISION_DIV1;
  htim4.Init.AutoReloadPreload = TIM_AUTORELOAD_PRELOAD_DISABLE;
  sConfig.EncoderMode = TIM_ENCODERMODE_TI12;
  sConfig.IC1Polarity = TIM_ICPOLARITY_RISING;
  sConfig.IC1Selection = TIM_ICSELECTION_DIRECTTI;
  sConfig.IC1Prescaler = TIM_ICPSC_DIV1;
  sConfig.IC1Filter = 15;
  sConfig.IC2Polarity = TIM_ICPOLARITY_RISING;
  sConfig.IC2Selection = TIM_ICSELECTION_DIRECTTI;
  sConfig.IC2Prescaler = TIM_ICPSC_DIV1;
  sConfig.IC2Filter = 15;
  if (HAL_TIM_Encoder_Init(&htim4, &sConfig) != HAL_OK)
  {
    _Error_Handler(__FILE__, __LINE__);
  }

  sMasterConfig.MasterOutputTrigger = TIM_TRGO_RESET;
  sMasterConfig.MasterSlaveMode = TIM_MASTERSLAVEMODE_DISABLE;
  if (HAL_TIMEx_MasterConfigSynchronization(&htim4, &sMasterConfig) != HAL_OK)
  {
    _Error_Handler(__FILE__, __LINE__);
  }

}

/* TIM5 init function */
static void MX_TIM5_Init(void)
{

  TIM_Encoder_InitTypeDef sConfig;
  TIM_MasterConfigTypeDef sMasterConfig;
  TIM_IC_InitTypeDef sConfigIC;

  htim5.Instance = TIM5;
  htim5.Init.Prescaler = 0;
  htim5.Init.CounterMode = TIM_COUNTERMODE_UP;
  htim5.Init.Period = 0;
  htim5.Init.ClockDivision = TIM_CLOCKDIVISION_DIV1;
  htim5.Init.AutoReloadPreload = TIM_AUTORELOAD_PRELOAD_DISABLE;
  if (HAL_TIM_IC_Init(&htim5) != HAL_OK)
  {
    _Error_Handler(__FILE__, __LINE__);
  }

  sConfig.EncoderMode = TIM_ENCODERMODE_TI1;
  sConfig.IC1Polarity = TIM_ICPOLARITY_RISING;
  sConfig.IC1Selection = TIM_ICSELECTION_DIRECTTI;
  sConfig.IC1Prescaler = TIM_ICPSC_DIV1;
  sConfig.IC1Filter = 0;
  sConfig.IC2Polarity = TIM_ICPOLARITY_RISING;
  sConfig.IC2Selection = TIM_ICSELECTION_DIRECTTI;
  sConfig.IC2Prescaler = TIM_ICPSC_DIV1;
  sConfig.IC2Filter = 0;
  if (HAL_TIM_Encoder_Init(&htim5, &sConfig) != HAL_OK)
  {
    _Error_Handler(__FILE__, __LINE__);
  }

  sMasterConfig.MasterOutputTrigger = TIM_TRGO_RESET;
  sMasterConfig.MasterSlaveMode = TIM_MASTERSLAVEMODE_DISABLE;
  if (HAL_TIMEx_MasterConfigSynchronization(&htim5, &sMasterConfig) != HAL_OK)
  {
    _Error_Handler(__FILE__, __LINE__);
  }

  sConfigIC.ICPolarity = TIM_INPUTCHANNELPOLARITY_RISING;
  sConfigIC.ICSelection = TIM_ICSELECTION_DIRECTTI;
  sConfigIC.ICPrescaler = TIM_ICPSC_DIV1;
  sConfigIC.ICFilter = 0;
  if (HAL_TIM_IC_ConfigChannel(&htim5, &sConfigIC, TIM_CHANNEL_3) != HAL_OK)
  {
    _Error_Handler(__FILE__, __LINE__);
  }

}

/* TIM6 init function */
static void MX_TIM6_Init(void)
{

  TIM_MasterConfigTypeDef sMasterConfig;

  htim6.Instance = TIM6;
  htim6.Init.Prescaler = 107;
  htim6.Init.CounterMode = TIM_COUNTERMODE_UP;
  htim6.Init.Period = 9999;
  htim6.Init.AutoReloadPreload = TIM_AUTORELOAD_PRELOAD_DISABLE;
  if (HAL_TIM_Base_Init(&htim6) != HAL_OK)
  {
    _Error_Handler(__FILE__, __LINE__);
  }

  sMasterConfig.MasterOutputTrigger = TIM_TRGO_RESET;
  sMasterConfig.MasterSlaveMode = TIM_MASTERSLAVEMODE_DISABLE;
  if (HAL_TIMEx_MasterConfigSynchronization(&htim6, &sMasterConfig) != HAL_OK)
  {
    _Error_Handler(__FILE__, __LINE__);
  }

}

/* TIM7 init function */
static void MX_TIM7_Init(void)
{

  TIM_MasterConfigTypeDef sMasterConfig;

  htim7.Instance = TIM7;
  htim7.Init.Prescaler = 107;
  htim7.Init.CounterMode = TIM_COUNTERMODE_UP;
  htim7.Init.Period = 9999;
  htim7.Init.AutoReloadPreload = TIM_AUTORELOAD_PRELOAD_DISABLE;
  if (HAL_TIM_Base_Init(&htim7) != HAL_OK)
  {
    _Error_Handler(__FILE__, __LINE__);
  }

  sMasterConfig.MasterOutputTrigger = TIM_TRGO_RESET;
  sMasterConfig.MasterSlaveMode = TIM_MASTERSLAVEMODE_DISABLE;
  if (HAL_TIMEx_MasterConfigSynchronization(&htim7, &sMasterConfig) != HAL_OK)
  {
    _Error_Handler(__FILE__, __LINE__);
  }

}

/* TIM8 init function */
static void MX_TIM8_Init(void)
{

  TIM_Encoder_InitTypeDef sConfig;
  TIM_MasterConfigTypeDef sMasterConfig;
  TIM_IC_InitTypeDef sConfigIC;

  htim8.Instance = TIM8;
  htim8.Init.Prescaler = 0;
  htim8.Init.CounterMode = TIM_COUNTERMODE_UP;
  htim8.Init.Period = 0;
  htim8.Init.ClockDivision = TIM_CLOCKDIVISION_DIV1;
  htim8.Init.RepetitionCounter = 0;
  htim8.Init.AutoReloadPreload = TIM_AUTORELOAD_PRELOAD_DISABLE;
  if (HAL_TIM_IC_Init(&htim8) != HAL_OK)
  {
    _Error_Handler(__FILE__, __LINE__);
  }

  sConfig.EncoderMode = TIM_ENCODERMODE_TI1;
  sConfig.IC1Polarity = TIM_ICPOLARITY_RISING;
  sConfig.IC1Selection = TIM_ICSELECTION_DIRECTTI;
  sConfig.IC1Prescaler = TIM_ICPSC_DIV1;
  sConfig.IC1Filter = 0;
  sConfig.IC2Polarity = TIM_ICPOLARITY_RISING;
  sConfig.IC2Selection = TIM_ICSELECTION_DIRECTTI;
  sConfig.IC2Prescaler = TIM_ICPSC_DIV1;
  sConfig.IC2Filter = 0;
  if (HAL_TIM_Encoder_Init(&htim8, &sConfig) != HAL_OK)
  {
    _Error_Handler(__FILE__, __LINE__);
  }

  sMasterConfig.MasterOutputTrigger = TIM_TRGO_RESET;
  sMasterConfig.MasterOutputTrigger2 = TIM_TRGO2_RESET;
  sMasterConfig.MasterSlaveMode = TIM_MASTERSLAVEMODE_DISABLE;
  if (HAL_TIMEx_MasterConfigSynchronization(&htim8, &sMasterConfig) != HAL_OK)
  {
    _Error_Handler(__FILE__, __LINE__);
  }

  sConfigIC.ICPolarity = TIM_INPUTCHANNELPOLARITY_RISING;
  sConfigIC.ICSelection = TIM_ICSELECTION_DIRECTTI;
  sConfigIC.ICPrescaler = TIM_ICPSC_DIV1;
  sConfigIC.ICFilter = 0;
  if (HAL_TIM_IC_ConfigChannel(&htim8, &sConfigIC, TIM_CHANNEL_3) != HAL_OK)
  {
    _Error_Handler(__FILE__, __LINE__);
  }

}

/* TIM9 init function */
static void MX_TIM9_Init(void)
{

  TIM_ClockConfigTypeDef sClockSourceConfig;
  TIM_OC_InitTypeDef sConfigOC;

  htim9.Instance = TIM9;
  htim9.Init.Prescaler = 1;
  htim9.Init.CounterMode = TIM_COUNTERMODE_UP;
  htim9.Init.Period = 4999;
  htim9.Init.ClockDivision = TIM_CLOCKDIVISION_DIV1;
  htim9.Init.AutoReloadPreload = TIM_AUTORELOAD_PRELOAD_DISABLE;
  if (HAL_TIM_Base_Init(&htim9) != HAL_OK)
  {
    _Error_Handler(__FILE__, __LINE__);
  }

  sClockSourceConfig.ClockSource = TIM_CLOCKSOURCE_INTERNAL;
  if (HAL_TIM_ConfigClockSource(&htim9, &sClockSourceConfig) != HAL_OK)
  {
    _Error_Handler(__FILE__, __LINE__);
  }

  if (HAL_TIM_PWM_Init(&htim9) != HAL_OK)
  {
    _Error_Handler(__FILE__, __LINE__);
  }

  sConfigOC.OCMode = TIM_OCMODE_PWM1;
  sConfigOC.Pulse = 0;
  sConfigOC.OCPolarity = TIM_OCPOLARITY_HIGH;
  sConfigOC.OCFastMode = TIM_OCFAST_DISABLE;
  if (HAL_TIM_PWM_ConfigChannel(&htim9, &sConfigOC, TIM_CHANNEL_1) != HAL_OK)
  {
    _Error_Handler(__FILE__, __LINE__);
  }

  sConfigOC.OCFastMode = TIM_OCFAST_ENABLE;
  if (HAL_TIM_PWM_ConfigChannel(&htim9, &sConfigOC, TIM_CHANNEL_2) != HAL_OK)
  {
    _Error_Handler(__FILE__, __LINE__);
  }

  HAL_TIM_MspPostInit(&htim9);

}

/* TIM10 init function */
static void MX_TIM10_Init(void)
{

  TIM_OC_InitTypeDef sConfigOC;

  htim10.Instance = TIM10;
  htim10.Init.Prescaler = 11;
  htim10.Init.CounterMode = TIM_COUNTERMODE_UP;
  htim10.Init.Period = 65535;
  htim10.Init.ClockDivision = TIM_CLOCKDIVISION_DIV1;
  htim10.Init.AutoReloadPreload = TIM_AUTORELOAD_PRELOAD_DISABLE;
  if (HAL_TIM_Base_Init(&htim10) != HAL_OK)
  {
    _Error_Handler(__FILE__, __LINE__);
  }

  if (HAL_TIM_PWM_Init(&htim10) != HAL_OK)
  {
    _Error_Handler(__FILE__, __LINE__);
  }

  if (HAL_TIM_OnePulse_Init(&htim10, TIM_OPMODE_SINGLE) != HAL_OK)
  {
    _Error_Handler(__FILE__, __LINE__);
  }

  sConfigOC.OCMode = TIM_OCMODE_PWM2;
  sConfigOC.Pulse = 0;
  sConfigOC.OCPolarity = TIM_OCPOLARITY_HIGH;
  sConfigOC.OCFastMode = TIM_OCFAST_ENABLE;
  if (HAL_TIM_PWM_ConfigChannel(&htim10, &sConfigOC, TIM_CHANNEL_1) != HAL_OK)
  {
    _Error_Handler(__FILE__, __LINE__);
  }

  HAL_TIM_MspPostInit(&htim10);

}

/* TIM11 init function */
static void MX_TIM11_Init(void)
{

  TIM_OC_InitTypeDef sConfigOC;

  htim11.Instance = TIM11;
  htim11.Init.Prescaler = 11;
  htim11.Init.CounterMode = TIM_COUNTERMODE_UP;
  htim11.Init.Period = 65535;
  htim11.Init.ClockDivision = TIM_CLOCKDIVISION_DIV1;
  htim11.Init.AutoReloadPreload = TIM_AUTORELOAD_PRELOAD_DISABLE;
  if (HAL_TIM_Base_Init(&htim11) != HAL_OK)
  {
    _Error_Handler(__FILE__, __LINE__);
  }

  if (HAL_TIM_PWM_Init(&htim11) != HAL_OK)
  {
    _Error_Handler(__FILE__, __LINE__);
  }

  if (HAL_TIM_OnePulse_Init(&htim11, TIM_OPMODE_SINGLE) != HAL_OK)
  {
    _Error_Handler(__FILE__, __LINE__);
  }

  sConfigOC.OCMode = TIM_OCMODE_PWM1;
  sConfigOC.Pulse = 0;
  sConfigOC.OCPolarity = TIM_OCPOLARITY_HIGH;
  sConfigOC.OCFastMode = TIM_OCFAST_DISABLE;
  if (HAL_TIM_PWM_ConfigChannel(&htim11, &sConfigOC, TIM_CHANNEL_1) != HAL_OK)
  {
    _Error_Handler(__FILE__, __LINE__);
  }

  HAL_TIM_MspPostInit(&htim11);

}

/* TIM12 init function */
static void MX_TIM12_Init(void)
{

  TIM_ClockConfigTypeDef sClockSourceConfig;
  TIM_OC_InitTypeDef sConfigOC;

  htim12.Instance = TIM12;
  htim12.Init.Prescaler = 0;
  htim12.Init.CounterMode = TIM_COUNTERMODE_UP;
  htim12.Init.Period = 4999;
  htim12.Init.ClockDivision = TIM_CLOCKDIVISION_DIV1;
  htim12.Init.AutoReloadPreload = TIM_AUTORELOAD_PRELOAD_DISABLE;
  if (HAL_TIM_Base_Init(&htim12) != HAL_OK)
  {
    _Error_Handler(__FILE__, __LINE__);
  }

  sClockSourceConfig.ClockSource = TIM_CLOCKSOURCE_INTERNAL;
  if (HAL_TIM_ConfigClockSource(&htim12, &sClockSourceConfig) != HAL_OK)
  {
    _Error_Handler(__FILE__, __LINE__);
  }

  if (HAL_TIM_PWM_Init(&htim12) != HAL_OK)
  {
    _Error_Handler(__FILE__, __LINE__);
  }

  sConfigOC.OCMode = TIM_OCMODE_PWM1;
  sConfigOC.Pulse = 0;
  sConfigOC.OCPolarity = TIM_OCPOLARITY_HIGH;
  sConfigOC.OCFastMode = TIM_OCFAST_DISABLE;
  if (HAL_TIM_PWM_ConfigChannel(&htim12, &sConfigOC, TIM_CHANNEL_1) != HAL_OK)
  {
    _Error_Handler(__FILE__, __LINE__);
  }

  if (HAL_TIM_PWM_ConfigChannel(&htim12, &sConfigOC, TIM_CHANNEL_2) != HAL_OK)
  {
    _Error_Handler(__FILE__, __LINE__);
  }

  HAL_TIM_MspPostInit(&htim12);

}

/* TIM13 init function */
static void MX_TIM13_Init(void)
{

  htim13.Instance = TIM13;
  htim13.Init.Prescaler = 1079;
  htim13.Init.CounterMode = TIM_COUNTERMODE_UP;
  htim13.Init.Period = 9999;
  htim13.Init.ClockDivision = TIM_CLOCKDIVISION_DIV1;
  htim13.Init.AutoReloadPreload = TIM_AUTORELOAD_PRELOAD_DISABLE;
  if (HAL_TIM_Base_Init(&htim13) != HAL_OK)
  {
    _Error_Handler(__FILE__, __LINE__);
  }

}

/* TIM14 init function */
static void MX_TIM14_Init(void)
{

  TIM_OC_InitTypeDef sConfigOC;

  htim14.Instance = TIM14;
  htim14.Init.Prescaler = 1;
  htim14.Init.CounterMode = TIM_COUNTERMODE_UP;
  htim14.Init.Period = 53999;
  htim14.Init.ClockDivision = TIM_CLOCKDIVISION_DIV1;
  htim14.Init.AutoReloadPreload = TIM_AUTORELOAD_PRELOAD_DISABLE;
  if (HAL_TIM_Base_Init(&htim14) != HAL_OK)
  {
    _Error_Handler(__FILE__, __LINE__);
  }

  if (HAL_TIM_PWM_Init(&htim14) != HAL_OK)
  {
    _Error_Handler(__FILE__, __LINE__);
  }

  sConfigOC.OCMode = TIM_OCMODE_PWM1;
  sConfigOC.Pulse = 27000;
  sConfigOC.OCPolarity = TIM_OCPOLARITY_HIGH;
  sConfigOC.OCFastMode = TIM_OCFAST_DISABLE;
  if (HAL_TIM_PWM_ConfigChannel(&htim14, &sConfigOC, TIM_CHANNEL_1) != HAL_OK)
  {
    _Error_Handler(__FILE__, __LINE__);
  }

  HAL_TIM_MspPostInit(&htim14);

}

/* UART7 init function */
static void MX_UART7_Init(void)
{

  huart7.Instance = UART7;
  huart7.Init.BaudRate = 115200;
  huart7.Init.WordLength = UART_WORDLENGTH_8B;
  huart7.Init.StopBits = UART_STOPBITS_1;
  huart7.Init.Parity = UART_PARITY_NONE;
  huart7.Init.Mode = UART_MODE_TX_RX;
  huart7.Init.HwFlowCtl = UART_HWCONTROL_NONE;
  huart7.Init.OverSampling = UART_OVERSAMPLING_16;
  huart7.Init.OneBitSampling = UART_ONE_BIT_SAMPLE_DISABLE;
  huart7.AdvancedInit.AdvFeatureInit = UART_ADVFEATURE_NO_INIT;
  if (HAL_UART_Init(&huart7) != HAL_OK)
  {
    _Error_Handler(__FILE__, __LINE__);
  }

}

/** Configure pins as
        * Analog
        * Input
        * Output
        * EVENT_OUT
        * EXTI
*/
static void MX_GPIO_Init(void)
{

  GPIO_InitTypeDef GPIO_InitStruct;

  /* GPIO Ports Clock Enable */
  __HAL_RCC_GPIOE_CLK_ENABLE();
  __HAL_RCC_GPIOC_CLK_ENABLE();
  __HAL_RCC_GPIOF_CLK_ENABLE();
  __HAL_RCC_GPIOH_CLK_ENABLE();
  __HAL_RCC_GPIOA_CLK_ENABLE();
  __HAL_RCC_GPIOB_CLK_ENABLE();
  __HAL_RCC_GPIOG_CLK_ENABLE();
  __HAL_RCC_GPIOD_CLK_ENABLE();

  /*Configure GPIO pin Output Level */
  HAL_GPIO_WritePin(GPIOC, M1_DIR_Pin|RxNRF_CE_Pin|Buzzer_Pin, GPIO_PIN_RESET);

  /*Configure GPIO pin Output Level */
  HAL_GPIO_WritePin(Charger_En_GPIO_Port, Charger_En_Pin, GPIO_PIN_RESET);

  /*Configure GPIO pin Output Level */
  HAL_GPIO_WritePin(GPIOB, TxNRF_CE_Pin|SP_DIR_Pin|SP_Sleep_Pin, GPIO_PIN_RESET);

  /*Configure GPIO pin Output Level */
  HAL_GPIO_WritePin(M3_DIR_GPIO_Port, M3_DIR_Pin, GPIO_PIN_RESET);

  /*Configure GPIO pin Output Level */
  HAL_GPIO_WritePin(M4_DIR_GPIO_Port, M4_DIR_Pin, GPIO_PIN_RESET);

  /*Configure GPIO pin Output Level */
  HAL_GPIO_WritePin(GPIOD, LED_0_Pin|LED_1_Pin|LED_2_Pin|LED_3_Pin
                          |LED_4_Pin|LED_5_Pin|LED_6_Pin|LED_7_Pin, GPIO_PIN_RESET);

  /*Configure GPIO pin Output Level */
  HAL_GPIO_WritePin(M2_DIR_GPIO_Port, M2_DIR_Pin, GPIO_PIN_RESET);

  /*Configure GPIO pins : M2_FF1_Pin M2_FF2_Pin M2_CLimitE1_Pin */
  GPIO_InitStruct.Pin = M2_FF1_Pin|M2_FF2_Pin|M2_CLimitE1_Pin;
  GPIO_InitStruct.Mode = GPIO_MODE_INPUT;
  GPIO_InitStruct.Pull = GPIO_NOPULL;
  HAL_GPIO_Init(GPIOE, &GPIO_InitStruct);

  /*Configure GPIO pins : M1_DIR_Pin RxNRF_CE_Pin Buzzer_Pin */
  GPIO_InitStruct.Pin = M1_DIR_Pin|RxNRF_CE_Pin|Buzzer_Pin;
  GPIO_InitStruct.Mode = GPIO_MODE_OUTPUT_PP;
  GPIO_InitStruct.Pull = GPIO_NOPULL;
  GPIO_InitStruct.Speed = GPIO_SPEED_FREQ_LOW;
  HAL_GPIO_Init(GPIOC, &GPIO_InitStruct);

  /*Configure GPIO pins : M1_FF1_Pin M1_FF2_Pin M4_CLimit_Pin M4_FF1_Pin
                           M4_FF2_Pin */
  GPIO_InitStruct.Pin = M1_FF1_Pin|M1_FF2_Pin|M4_CLimit_Pin|M4_FF1_Pin
                          |M4_FF2_Pin;
  GPIO_InitStruct.Mode = GPIO_MODE_INPUT;
  GPIO_InitStruct.Pull = GPIO_NOPULL;
  HAL_GPIO_Init(GPIOC, &GPIO_InitStruct);

  /*Configure GPIO pins : Error_Flag_Pin M1_CLimit_Pin M1_FF1F11_Pin M1_FF2F12_Pin
                           Ball_Flag_Pin */
  GPIO_InitStruct.Pin = Error_Flag_Pin|M1_CLimit_Pin|M1_FF1F11_Pin|M1_FF2F12_Pin
                          |Ball_Flag_Pin;
  GPIO_InitStruct.Mode = GPIO_MODE_INPUT;
  GPIO_InitStruct.Pull = GPIO_NOPULL;
  HAL_GPIO_Init(GPIOF, &GPIO_InitStruct);

  /*Configure GPIO pin : Charger_En_Pin */
  GPIO_InitStruct.Pin = Charger_En_Pin;
  GPIO_InitStruct.Mode = GPIO_MODE_OUTPUT_PP;
  GPIO_InitStruct.Pull = GPIO_NOPULL;
  GPIO_InitStruct.Speed = GPIO_SPEED_FREQ_LOW;
  HAL_GPIO_Init(Charger_En_GPIO_Port, &GPIO_InitStruct);

  /*Configure GPIO pin : M2_CLimit_Pin */
  GPIO_InitStruct.Pin = M2_CLimit_Pin;
  GPIO_InitStruct.Mode = GPIO_MODE_INPUT;
  GPIO_InitStruct.Pull = GPIO_NOPULL;
  HAL_GPIO_Init(M2_CLimit_GPIO_Port, &GPIO_InitStruct);

  /*Configure GPIO pin : RxNRF_IRQ_Pin */
  GPIO_InitStruct.Pin = RxNRF_IRQ_Pin;
  GPIO_InitStruct.Mode = GPIO_MODE_IT_RISING;
  GPIO_InitStruct.Pull = GPIO_NOPULL;
  HAL_GPIO_Init(RxNRF_IRQ_GPIO_Port, &GPIO_InitStruct);

  /*Configure GPIO pin : TxNRF_IRQ_Pin */
  GPIO_InitStruct.Pin = TxNRF_IRQ_Pin;
  GPIO_InitStruct.Mode = GPIO_MODE_IT_RISING;
  GPIO_InitStruct.Pull = GPIO_NOPULL;
  HAL_GPIO_Init(TxNRF_IRQ_GPIO_Port, &GPIO_InitStruct);

  /*Configure GPIO pins : TxNRF_CE_Pin SP_DIR_Pin SP_Sleep_Pin */
  GPIO_InitStruct.Pin = TxNRF_CE_Pin|SP_DIR_Pin|SP_Sleep_Pin;
  GPIO_InitStruct.Mode = GPIO_MODE_OUTPUT_PP;
  GPIO_InitStruct.Pull = GPIO_NOPULL;
  GPIO_InitStruct.Speed = GPIO_SPEED_FREQ_LOW;
  HAL_GPIO_Init(GPIOB, &GPIO_InitStruct);

  /*Configure GPIO pins : M3_FF2_Pin M3_FF1_Pin M3_CLimit_Pin BACK_KEY_Pin
                           UP_KEY_Pin ENTER_KEY_Pin DOWN_KEY_Pin Charge_En_Pin */
  GPIO_InitStruct.Pin = M3_FF2_Pin|M3_FF1_Pin|M3_CLimit_Pin|BACK_KEY_Pin
                          |UP_KEY_Pin|ENTER_KEY_Pin|DOWN_KEY_Pin|Charge_En_Pin;
  GPIO_InitStruct.Mode = GPIO_MODE_INPUT;
  GPIO_InitStruct.Pull = GPIO_NOPULL;
  HAL_GPIO_Init(GPIOG, &GPIO_InitStruct);

  /*Configure GPIO pin : M3_DIR_Pin */
  GPIO_InitStruct.Pin = M3_DIR_Pin;
  GPIO_InitStruct.Mode = GPIO_MODE_OUTPUT_PP;
  GPIO_InitStruct.Pull = GPIO_NOPULL;
  GPIO_InitStruct.Speed = GPIO_SPEED_FREQ_LOW;
  HAL_GPIO_Init(M3_DIR_GPIO_Port, &GPIO_InitStruct);

  /*Configure GPIO pin : M4_DIR_Pin */
  GPIO_InitStruct.Pin = M4_DIR_Pin;
  GPIO_InitStruct.Mode = GPIO_MODE_OUTPUT_PP;
  GPIO_InitStruct.Pull = GPIO_NOPULL;
  GPIO_InitStruct.Speed = GPIO_SPEED_FREQ_LOW;
  HAL_GPIO_Init(M4_DIR_GPIO_Port, &GPIO_InitStruct);

  /*Configure GPIO pins : LED_0_Pin LED_1_Pin LED_2_Pin LED_3_Pin
                           LED_4_Pin LED_5_Pin LED_6_Pin LED_7_Pin */
  GPIO_InitStruct.Pin = LED_0_Pin|LED_1_Pin|LED_2_Pin|LED_3_Pin
                          |LED_4_Pin|LED_5_Pin|LED_6_Pin|LED_7_Pin;
  GPIO_InitStruct.Mode = GPIO_MODE_OUTPUT_PP;
  GPIO_InitStruct.Pull = GPIO_NOPULL;
  GPIO_InitStruct.Speed = GPIO_SPEED_FREQ_LOW;
  HAL_GPIO_Init(GPIOD, &GPIO_InitStruct);

  /*Configure GPIO pin : M2_DIR_Pin */
  GPIO_InitStruct.Pin = M2_DIR_Pin;
  GPIO_InitStruct.Mode = GPIO_MODE_OUTPUT_PP;
  GPIO_InitStruct.Pull = GPIO_NOPULL;
  GPIO_InitStruct.Speed = GPIO_SPEED_FREQ_LOW;
  HAL_GPIO_Init(M2_DIR_GPIO_Port, &GPIO_InitStruct);

}

/* USER CODE BEGIN 4 */
void Set_PWM (int M1_PWM,int M2_PWM,int M3_PWM,int M4_PWM,int SP_PWM)
{
		if(M1_PWM < 0)
	{
		if(M1_PWM < -2500)
			M1_PWM = -2500;

		__HAL_TIM_SET_COMPARE(&htim9, TIM_CHANNEL_2, M1_PWM + 2500);
//		HAL_GPIO_WritePin(M1_DIR_GPIO_Port,M1_DIR_Pin,GPIO_PIN_SET);
	}
	else
	{

		if(M1_PWM > 2500)
			M1_PWM = 2500;

		__HAL_TIM_SET_COMPARE(&htim9, TIM_CHANNEL_2, M1_PWM + 2500);
//		HAL_GPIO_WritePin(M1_DIR_GPIO_Port,M1_DIR_Pin,GPIO_PIN_RESET);
	}
//
//	if(right_pwm < 0)
//	{
//		if(right_pwm < -MAX_PWM)
//			right_pwm = -MAX_PWM;
//
//		__HAL_TIM_SET_COMPARE(&htim9, MOTOR_CH_R_1, -right_pwm);
//		__HAL_TIM_SET_COMPARE(&htim9, MOTOR_CH_R_2, 0);
//	}
//	else
//	{
//		if(right_pwm > MAX_PWM)
//			right_pwm = MAX_PWM;
//
//		__HAL_TIM_SET_COMPARE(&htim9, MOTOR_CH_R_1, 0);
//		__HAL_TIM_SET_COMPARE(&htim9, MOTOR_CH_R_2, right_pwm);
//	}
//}

//			__HAL_TIM_SetCompare(&htim9,TIM_CHANNEL_2,M1_PWM+2500);   //M1
//			__HAL_TIM_SetCompare(&htim9,TIM_CHANNEL_1,M2_PWM+2500); 	//M2
//			__HAL_TIM_SetCompare(&htim12,TIM_CHANNEL_1,M3_PWM+2500);  //M3
//		  __HAL_TIM_SetCompare(&htim12,TIM_CHANNEL_2,M4_PWM+2500);  //M4
//			__HAL_TIM_SetCompare(&htim2,TIM_CHANNEL_4,2*SP_PWM); 			//SP
}
void OLED_Preview (float Value)
{
			char buffer[14];
			sprintf(buffer,"Desired = %4d",Value);
			ssd1306_SetCursor(0,10);
			ssd1306_WriteString(buffer,Font_7x10,White);
			ssd1306_UpdateScreen();
}

bool PB_UPKey(void)
{
	if(HAL_GPIO_ReadPin(UP_KEY_GPIO_Port,UP_KEY_Pin))
	{
//	    HAL_Delay(1);
		if(HAL_GPIO_ReadPin(UP_KEY_GPIO_Port,UP_KEY_Pin))
			return true;
	}
	return false;
}

bool PB_DOWNKey(void)
{
	if(HAL_GPIO_ReadPin(DOWN_KEY_GPIO_Port,DOWN_KEY_Pin))
	{
//	    HAL_Delay(1);
		if(HAL_GPIO_ReadPin(DOWN_KEY_GPIO_Port,DOWN_KEY_Pin))
			return true;
	}
	return false;
}

bool PB_ENTERKey(void)
{
	if(HAL_GPIO_ReadPin(ENTER_KEY_GPIO_Port,ENTER_KEY_Pin))
	{
//	    HAL_Delay(1);
		if(HAL_GPIO_ReadPin(ENTER_KEY_GPIO_Port,ENTER_KEY_Pin))
			return true;
	}
	return false;
}
bool PB_BACKKey(void)
{
	if(HAL_GPIO_ReadPin(BACK_KEY_GPIO_Port,BACK_KEY_Pin))
	{
//	    HAL_Delay(1);
		if(HAL_GPIO_ReadPin(BACK_KEY_GPIO_Port,BACK_KEY_Pin))
			return true;
	}
	return false;
}

void PID(void)
{
						Error = Input_Speed - EN1_RPM;

						DifferentialError = (Error - LastError) * FRAME_RATE;

						IntegralError = (IntegralError * lambda ) + (Error *  PERIOD);

						if(IntegralError > MaxIntegral)
						{
						IntegralError = MaxIntegral;
						}
						else if(IntegralError < -MaxIntegral)
						{
							IntegralError = -MaxIntegral;
						}

					LastError = Error;

					output = ((Error * KP) +(IntegralError * KI) + ((DifferentialError) * KD));

					Set_PWM(output,0,0,0,0);
}

void Scan_Keys(void)
{
			if(PB_UPKey())
			{
			Input_Speed+=100;
			if(Input_Speed > 6500)
			Input_Speed = 6500;
//			OLED_Preview(Input_Speed);
			}
			if(PB_DOWNKey())
			{
			Input_Speed-=100;
			if(Input_Speed < 100)
			Input_Speed = 0;
//			OLED_Preview(Input_Speed);
			}

			if(PB_BACKKey())
			{
			Input_Speed = 0;
//			OLED_Preview(Input_Speed);
			}

		}

float Filter_Encoder_Data(float enc_data , float coeff , float last_filter)
{
	float rst = enc_data;
	rst = ( (coeff - 1)*last_filter + enc_data )/coeff;
	return rst;
}
/* USER CODE END 4 */

void _Error_Handler(char *file, int line)
{
  while(1)
  {
  }
}

/************************ (C) COPYRIGHT STMicroelectronics *****END OF FILE****/
